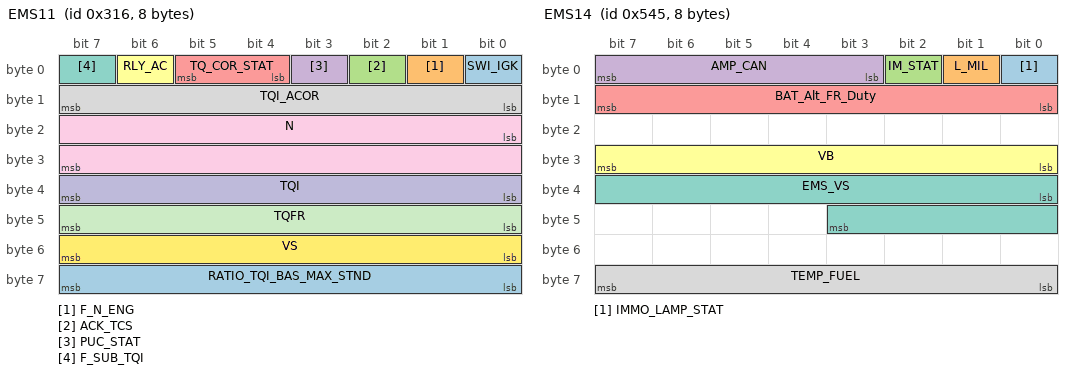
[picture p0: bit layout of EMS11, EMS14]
BO_ 790 EMS11: 8 EMS
 SG_ SWI_IGK : 0|1@1+ (1.0,0.0) [0.0|1.0] ""  _4WD,ABS,ACU,AHLS,CUBIS,DI_BOX,ECS,EPB,ESC,IBOX,LDWS_LKAS,MDPS,REA,SAS,SCC,TCU
 SG_ F_N_ENG : 1|1@1+ (1.0,0.0) [0.0|1.0] ""  _4WD,ACU,AFLS,CLU,CUBIS,DATC,ECS,EPB,ESC,IBOX,MDPS,SCC,TCU
 SG_ ACK_TCS : 2|1@1+ (1.0,0.0) [0.0|1.0] ""  ESC,IBOX
 SG_ PUC_STAT : 3|1@1+ (1.0,0.0) [0.0|1.0] ""  _4WD,CLU,DATC,IBOX,TCU
 SG_ TQ_COR_STAT : 4|2@1+ (1.0,0.0) [0.0|3.0] ""  _4WD,ESC,IBOX,TCU
 SG_ RLY_AC : 6|1@1+ (1.0,0.0) [0.0|1.0] ""  DATC,IBOX,TCU
 SG_ F_SUB_TQI : 7|1@1+ (1.0,0.0) [0.0|1.0] ""  _4WD,ECS,EPB,ESC,IBOX,TCU
 SG_ TQI_ACOR : 8|8@1+ (0.390625,0.0) [0.0|99.6094] "%"  _4WD,EPB,ESC,IBOX,TCU
 SG_ N : 16|16@1+ (0.25,0.0) [0.0|16383.75] "rpm"  _4WD,ACU,AFLS,CLU,CUBIS,DATC,ECS,EPB,ESC,FPCM,IBOX,MDPS,SCC,TCU
 SG_ TQI : 32|8@1+ (0.390625,0.0) [0.0|99.6094] "%"  _4WD,ECS,EPB,ESC,IBOX,TCU
 SG_ TQFR : 40|8@1+ (0.390625,0.0) [0.0|99.6094] "%"  _4WD,EPB,ESC,IBOX,TCU
 SG_ VS : 48|8@1+ (1.0,0.0) [0.0|254.0] "km/h"  _4WD,AAF,ACU,AHLS,BCM,CLU,DATC,ECS,EPB,IBOX,LCA,LDWS_LKAS,LVR,MDPS,ODS,SCC,SMK,SPAS,TCU,TPMS
 SG_ RATIO_TQI_BAS_MAX_STND : 56|8@1+ (0.0078,0.0) [0.0|2.0] ""  _4WD,IBOX,TCU

BO_ 1349 EMS14: 8 EMS
 SG_ IMMO_LAMP_STAT : 0|1@1+ (1.0,0.0) [0.0|1.0] ""  CLU,IBOX
 SG_ L_MIL : 1|1@1+ (1.0,0.0) [0.0|1.0] ""  CLU,CUBIS,IBOX
 SG_ IM_STAT : 2|1@1+ (1.0,0.0) [0.0|1.0] ""  CLU,IBOX
 SG_ AMP_CAN : 3|5@1+ (10.731613,458.98) [458.98|791.660003] "mmHg"  CLU,IBOX,TCU,TPMS
 SG_ BAT_Alt_FR_Duty : 8|8@1+ (0.4,0.0) [0.0|100.0] "%"  CGW,CUBIS,IBOX,TMU
 SG_ VB : 24|8@1+ (0.1015625,0.0) [0.0|25.8984375] "V"  CLU,CUBIS,DATC,EPB,FPCM,IBOX
 SG_ EMS_VS : 32|12@1+ (0.0625,0.0) [0.0|255.875] "km/h"  CLU
 SG_ TEMP_FUEL : 56|8@1+ (0.75,-48.0) [-48.0|143.25] "deg"  FPCM

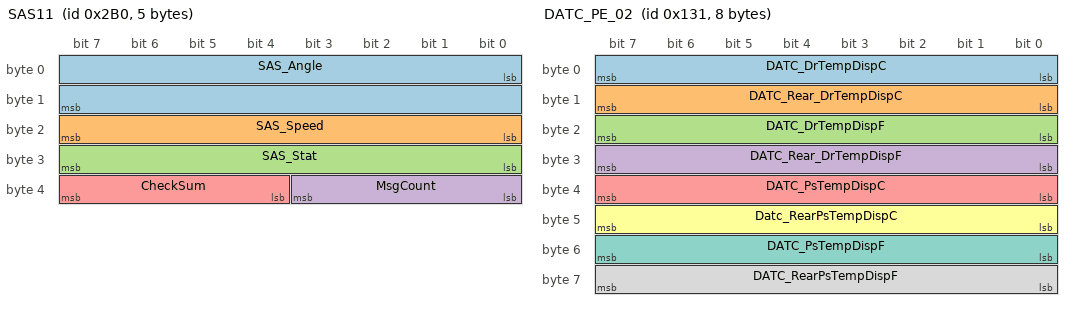
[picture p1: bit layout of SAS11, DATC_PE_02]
BO_ 688 SAS11: 5 MDPS
 SG_ SAS_Angle : 0|16@1- (0.1,0.0) [-3276.8|3276.7] "Deg"  _4WD,ACU,AFLS,AVM,CLU,ECS,EMS,ESC,IBOX,LCA,LDWS_LKAS,PGS,PSB,SCC,SPAS,TCU,_4WD,ACU,AFLS,AVM,BCM,CLU,ECS,EMS,ESC,IBOX,LCA,LDWS_LKAS,PGS,PSB,SCC,SPAS,TCU
 SG_ SAS_Speed : 16|8@1+ (4.0,0.0) [0.0|1016.0] ""  AFLS,ECS,ESC,IBOX,LDWS_LKAS,SCC,SPAS,TCU,AFLS,ECS,ESC,IBOX,LDWS_LKAS,SCC,SPAS,TCU
 SG_ SAS_Stat : 24|8@1+ (1.0,0.0) [0.0|255.0] ""  ECS,ESC,IBOX,LDWS_LKAS,PSB,SCC,SPAS,TCU,ECS,ESC,IBOX,LDWS_LKAS,PSB,SCC,SPAS,TCU
 SG_ MsgCount : 32|4@1+ (1.0,0.0) [0.0|15.0] ""  ECS,ESC,IBOX,LDWS_LKAS,PSB,SCC,SPAS,ECS,ESC,IBOX,LDWS_LKAS,PSB,SCC,SPAS
 SG_ CheckSum : 36|4@1+ (1.0,0.0) [0.0|15.0] ""  ECS,EMS,ESC,IBOX,LDWS_LKAS,PSB,SCC,SPAS,ECS,EMS,ESC,IBOX,LDWS_LKAS,PSB,SCC,SPAS

BO_ 809 EMS12: 8 EMS
 SG_ CONF_TCU_m1 : 0|6@1+ (1.0,0.0) [0.0|63.0] ""  _4WD,ACU,BCM,CLU,DATC,EPB,ESC,IBOX,LCA,SMK
 SG_ CAN_VERS_m0 : 0|6@1+ (1.0,0.0) [0.0|7.7] ""  _4WD,ABS,ESC,IBOX
 SG_ TQ_STND_m3 : 0|6@1+ (10.0,0.0) [0.0|630.0] "Nm"  _4WD,DATC,ECS,EPB,ESC,FATC,IBOX
 SG_ OBD_FRF_ACK_m2 : 0|6@1+ (1.0,0.0) [0.0|63.0] ""  _4WD,ESC,IBOX
 SG_ MUL_CODE_M : 6|2@1+ (1.0,0.0) [0.0|3.0] ""  _4WD,ABS,ACU,BCM,CLU,DATC,ECS,EPB,ESC,IBOX,LCA,SMK,TCU
 SG_ TEMP_ENG : 8|8@1+ (0.75,-48.0) [-48.0|143.25] "deg"  _4WD,BCM,CLU,DATC,EPB,ESC,IBOX,SMK,TCU
 SG_ MAF_FAC_ALTI_MMV : 16|8@1+ (0.00781,0.0) [0.0|1.99155] ""  IBOX,TCU
 SG_ VB_OFF_ACT : 24|1@1+ (1.0,0.0) [0.0|1.0] ""  IBOX,TCU
 SG_ ACK_ES : 25|1@1+ (1.0,0.0) [0.0|1.0] ""  _4WD,ACU,IBOX
 SG_ CONF_MIL_FMY : 26|3@1+ (1.0,0.0) [0.0|7.0] ""  ESC,IBOX,TCU
 SG_ OD_OFF_REQ : 29|1@1+ (1.0,0.0) [0.0|1.0] ""  IBOX,TCU
 SG_ ACC_ACT : 30|1@1+ (1.0,0.0) [0.0|1.0] ""  _4WD,ABS,CLU,ESC,IAP,IBOX,SCC,TCU
 SG_ CLU_ACK : 31|1@1+ (1.0,0.0) [0.0|1.0] ""  _4WD,EPB,ESC,IBOX
 SG_ BRAKE_ACT : 32|2@1+ (1.0,0.0) [0.0|3.0] ""  _4WD,ABS,ACU,AFLS,CLU,DATC,ECS,EPB,ESC,IBOX,LDWS_LKAS,TCU
 SG_ ENG_CHR : 34|4@1+ (1.0,0.0) [0.0|15.0] ""  _4WD,ABS,ACU,CLU,DATC,EPB,ESC,FATC,IBOX,SCC,SMK,TCU
 SG_ GP_CTL : 38|2@1+ (1.0,0.0) [0.0|3.0] ""  IBOX
 SG_ TPS : 40|8@1+ (0.4694836,-15.0234742) [-15.0234742|104.6948357] "%"  _4WD,ABS,ACU,CLU,DATC,ECS,EPB,ESC,IBOX,TCU
 SG_ PV_AV_CAN : 48|8@1+ (0.3906,0.0) [0.0|99.603] "%"  _4WD,AAF,ABS,ACU,AFLS,CLU,DATC,EPB,ESC,IAP,IBOX,LDWS_LKAS,SCC,TCU
 SG_ ENG_VOL : 56|8@1+ (0.1,0.0) [0.0|25.5] "liter"  _4WD,ABS,ACU,BCM,CLU,DATC,EPB,ESC,IBOX,LDWS_LKAS,SCC,SMK

 BO_ 305 DATC_PE_02: 8 CLU
 SG_ DATC_DrTempDispC : 7|8@0+ (0.5,14) [15|32] "C"  H_U,IBOX,MON
 SG_ DATC_Rear_DrTempDispC : 15|8@0+ (0.5,14) [15|32] "C"  H_U,IBOX,MON
 SG_ DATC_DrTempDispF : 23|8@0+ (1,56) [58|90] "F"  H_U,IBOX,MON
 SG_ DATC_Rear_DrTempDispF : 31|8@0+ (1,56) [58|90] "F"  H_U,IBOX,MON
 SG_ DATC_PsTempDispC : 39|8@0+ (0.5,14) [15|32] "C"  H_U,IBOX,MON
 SG_ Datc_RearPsTempDispC : 47|8@0+ (0.5,14) [15|32] "C"  H_U,IBOX,MON
 SG_ DATC_PsTempDispF : 55|8@0+ (1,56) [58|90] "F"  H_U,IBOX,MON
 SG_ DATC_RearPsTempDispF : 63|8@0+ (1,56) [58|90] "F"  H_U,IBOX,MON
